VERSION ""

NS_ :

BS_:

BU_: IVT AmsClient Ams PE_FR PE_FL PE_RR FrontNode PE_RL RearNode

BO_ 1 GpsState: 1 RearNode
 SG_ gps_ok : 0|1@1+ (1,0) [0|0] ""  RearNode

BO_ 197 GpsPosition: 8 FrontNode
 SG_ latitude : 0|32@1- (1,0) [0|0] "degrees"  RearNode
 SG_ longitude : 32|32@1- (1,0) [0|0] "degrees"  RearNode

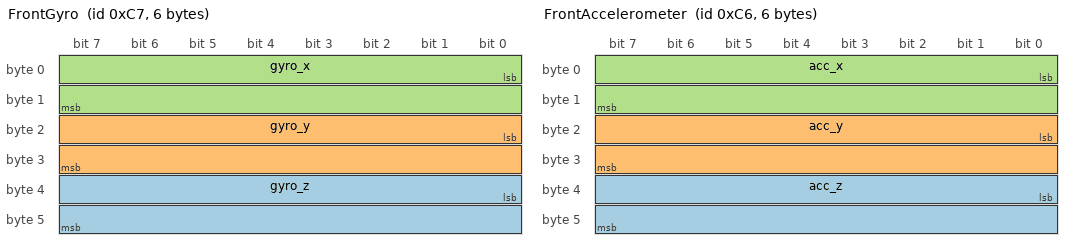
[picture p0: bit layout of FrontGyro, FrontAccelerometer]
BO_ 199 FrontGyro: 6 FrontNode
 SG_ gyro_z : 32|16@1- (1,0) [0|0] ""  FrontNode,RearNode
 SG_ gyro_y : 16|16@1- (1,0) [0|0] ""  FrontNode,RearNode
 SG_ gyro_x : 0|16@1- (1,0) [0|0] ""  FrontNode,RearNode

BO_ 198 FrontAccelerometer: 6 FrontNode
 SG_ acc_z : 32|16@1- (0.001,0) [0|0] "m/s^2"  FrontNode,RearNode
 SG_ acc_y : 16|16@1- (0.001,0) [0|0] "m/s^2"  FrontNode,RearNode
 SG_ acc_x : 0|16@1- (0.001,0) [0|0] "m/s^2"  FrontNode,RearNode

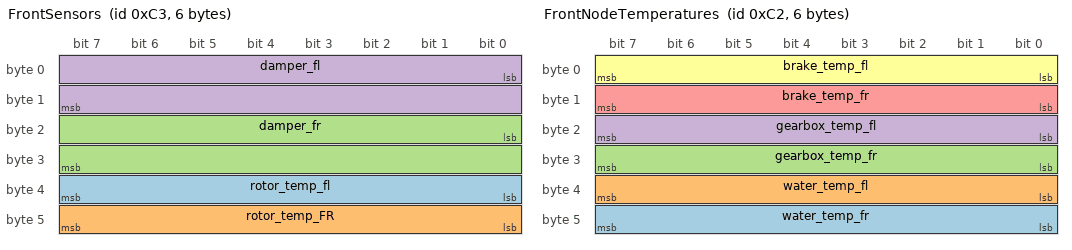
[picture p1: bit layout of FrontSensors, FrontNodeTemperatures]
BO_ 195 FrontSensors: 6 FrontNode
 SG_ rotor_temp_fl : 32|8@1+ (0.5,5) [5|132.5] "" Vector__XXX
 SG_ rotor_temp_FR : 40|8@1+ (0.5,5) [5|132.5] "" Vector__XXX
 SG_ damper_fr : 16|16@1+ (0.01,0) [0|655.35] ""  FrontNode,RearNode
 SG_ damper_fl : 0|16@1+ (0.01,0) [0|655.35] ""  FrontNode,RearNode

BO_ 194 FrontNodeTemperatures: 6 FrontNode
 SG_ water_temp_fr : 40|8@1+ (0.5,5) [5|132.5] "" Vector__XXX
 SG_ water_temp_fl : 32|8@1+ (0.5,5) [5|132.5] "" Vector__XXX
 SG_ gearbox_temp_fr : 24|8@1+ (0.5,5) [5|132.5] ""  FrontNode,RearNode
 SG_ gearbox_temp_fl : 16|8@1+ (0.5,5) [5|132.5] ""  FrontNode,RearNode
 SG_ brake_temp_fr : 8|8@1+ (4,0) [0|0] ""  FrontNode,RearNode
 SG_ brake_temp_fl : 0|8@1+ (4,0) [0|1020] ""  FrontNode,RearNode

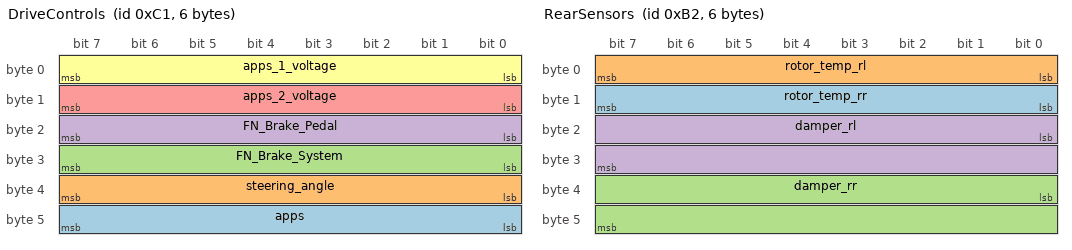
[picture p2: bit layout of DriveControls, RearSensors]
BO_ 193 DriveControls: 6 FrontNode
 SG_ apps : 40|8@1+ (0.5,0) [0|0] ""  FrontNode,RearNode
 SG_ steering_angle : 32|8@1- (2,0) [-256|254] ""  FrontNode,RearNode
 SG_ FN_Brake_System : 24|8@1+ (0.5,0) [0|0] ""  FrontNode,RearNode
 SG_ FN_Brake_Pedal : 16|8@1+ (0.5,0) [0|0] ""  FrontNode,RearNode
 SG_ apps_2_voltage : 8|8@1+ (0.5,0) [0|127.5] ""  FrontNode,RearNode
 SG_ apps_1_voltage : 0|8@1+ (0.5,0) [0|127.5] ""  FrontNode,RearNode

BO_ 178 RearSensors: 6 RearNode
 SG_ rotor_temp_rr : 8|8@1+ (0.5,5) [5|132.5] ""  FrontNode
 SG_ rotor_temp_rl : 0|8@1+ (0.5,5) [5|132.5] ""  FrontNode
 SG_ damper_rr : 32|16@1+ (0.01,0) [0|655.35] ""  FrontNode
 SG_ damper_rl : 16|16@1+ (0.01,0) [0|655.35] ""  FrontNode

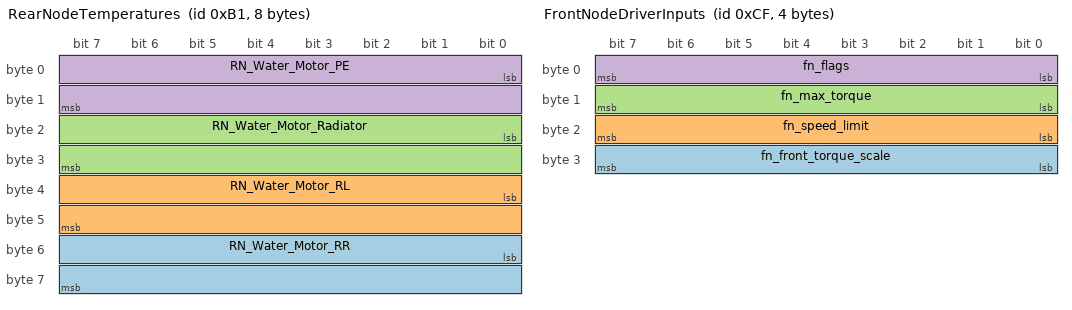
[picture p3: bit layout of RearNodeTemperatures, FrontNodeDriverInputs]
BO_ 177 RearNodeTemperatures: 8 RearNode
 SG_ RN_Water_Motor_RR : 48|16@1+ (0.01,0) [0|655.35] ""  FrontNode
 SG_ RN_Water_Motor_RL : 32|16@1+ (0.01,0) [0|655.35] ""  FrontNode
 SG_ RN_Water_Motor_Radiator : 16|16@1+ (0.01,0) [0|655.35] ""  FrontNode
 SG_ RN_Water_Motor_PE : 0|16@1+ (0.01,0) [0|655.35] ""  FrontNode

BO_ 207 FrontNodeDriverInputs: 4 FrontNode
 SG_ fn_front_torque_scale : 24|8@1+ (0.4,0) [0|102] ""  FrontNode
 SG_ fn_speed_limit : 16|8@1+ (100,0) [0|25500] ""  FrontNode
 SG_ fn_max_torque : 8|8@1+ (0.4,0) [0|102] ""  FrontNode
 SG_ fn_flags : 0|8@1+ (1,0) [0|0] ""  FrontNode,Ams,RearNode

BO_ 191 RearNodeStatus: 4 RearNode
 SG_ rn_state : 0|8@1+ (1,0) [0|0] ""  FrontNode

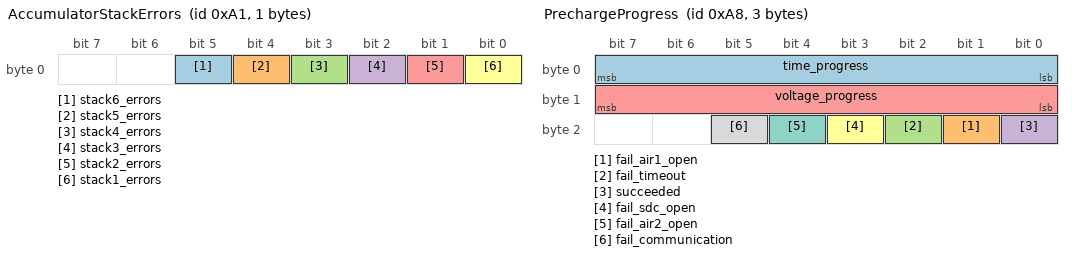
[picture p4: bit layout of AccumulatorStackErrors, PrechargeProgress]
BO_ 161 AccumulatorStackErrors: 1 Ams
 SG_ stack6_errors : 5|1@1+ (1,0) [0|0] ""  FrontNode,AmsClient
 SG_ stack5_errors : 4|1@1+ (1,0) [0|0] ""  FrontNode,AmsClient
 SG_ stack4_errors : 3|1@1+ (1,0) [0|0] ""  FrontNode,AmsClient
 SG_ stack3_errors : 2|1@1+ (1,0) [0|0] ""  FrontNode,AmsClient
 SG_ stack2_errors : 1|1@1+ (1,0) [0|0] ""  FrontNode,AmsClient
 SG_ stack1_errors : 0|1@1+ (1,0) [0|0] ""  FrontNode,AmsClient

BO_ 1320 IVT_Msg_Result_Wh: 6 IVT
 SG_ IVT_ResultState_And_MsgCount_Wh : 8|8@1- (1,0) [0|0] ""  Ams,AmsClient
 SG_ IVT_Result_Wh : 16|32@1- (1,0) [0|0] ""  Ams,AmsClient
 SG_ IVT_MuxID_Wh : 0|8@1+ (1,0) [0|0] ""  Ams,AmsClient

BO_ 1318 IVT_Msg_Result_W: 6 IVT
 SG_ IVT_ResultState_And_MsgCount_W : 8|8@1- (1,0) [0|0] ""  Ams,AmsClient
 SG_ IVT_Result_W : 16|32@1- (1,0) [0|0] ""  Ams,AmsClient
 SG_ IVT_MuxID_W : 0|8@1+ (1,0) [0|0] ""  Ams,AmsClient

BO_ 241 AmsClientStatus: 1 AmsClient
 SG_ AmsClient_Trigger_Ams : 0|1@1+ (1,0) [0|0] ""  Ams
 SG_ AmsClient_Start_TS : 1|1@1+ (1,0) [0|255] ""  Ams

BO_ 168 PrechargeProgress: 3 Ams
 SG_ time_progress : 0|8@1+ (1,0) [0|100] "%"  FrontNode,AmsClient
 SG_ fail_air1_open : 17|1@1+ (1,0) [0|0] "flag"  FrontNode,AmsClient
 SG_ fail_timeout : 18|1@1+ (1,0) [0|0] "flag"  FrontNode,AmsClient
 SG_ succeeded : 16|1@1+ (1,0) [0|0] "flag"  FrontNode,AmsClient
 SG_ voltage_progress : 8|8@1+ (1,0) [0|100] "%"  AmsClient
 SG_ fail_sdc_open : 19|1@1+ (1,0) [0|0] "flag"  AmsClient
 SG_ fail_air2_open : 20|1@1+ (1,0) [0|0] ""  AmsClient
 SG_ fail_communication : 21|1@1+ (1,0) [0|0] ""  AmsClient

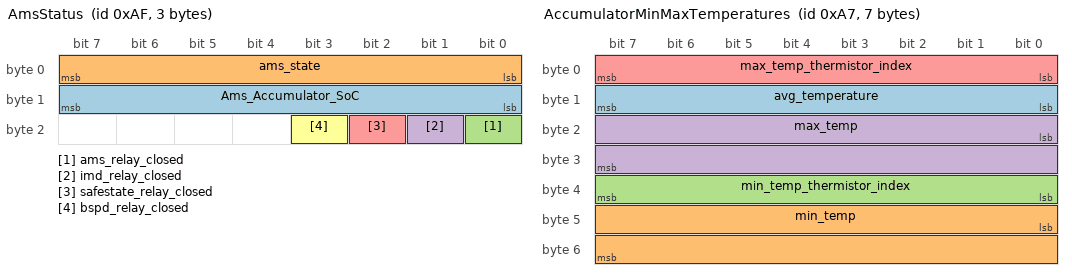
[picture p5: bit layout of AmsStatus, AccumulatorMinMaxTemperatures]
BO_ 175 AmsStatus: 3 Ams
 SG_ Ams_Accumulator_SoC : 8|8@1+ (1,0) [0|255] ""  FrontNode,AmsClient
 SG_ ams_state : 0|8@1+ (1,0) [0|3] ""  FrontNode,AmsClient
 SG_ ams_relay_closed : 16|1@1+ (1,0) [0|0] ""  AmsClient
 SG_ imd_relay_closed : 17|1@1+ (1,0) [0|0] ""  AmsClient
 SG_ safestate_relay_closed : 18|1@1+ (1,0) [0|0] ""  AmsClient
 SG_ bspd_relay_closed : 19|1@1+ (1,0) [0|0] ""  AmsClient

BO_ 167 AccumulatorMinMaxTemperatures: 7 Ams
 SG_ avg_temperature : 8|8@1- (1,0) [0|0] ""  AmsClient
 SG_ min_temp : 40|16@1- (0.01,0) [0|655.35] ""  FrontNode,AmsClient
 SG_ min_temp_thermistor_index : 32|8@1+ (1,0) [0|255] ""  FrontNode,AmsClient
 SG_ max_temp : 16|16@1- (0.01,0) [0|655.35] ""  FrontNode,AmsClient
 SG_ max_temp_thermistor_index : 0|8@1+ (1,0) [0|255] ""  FrontNode,AmsClient

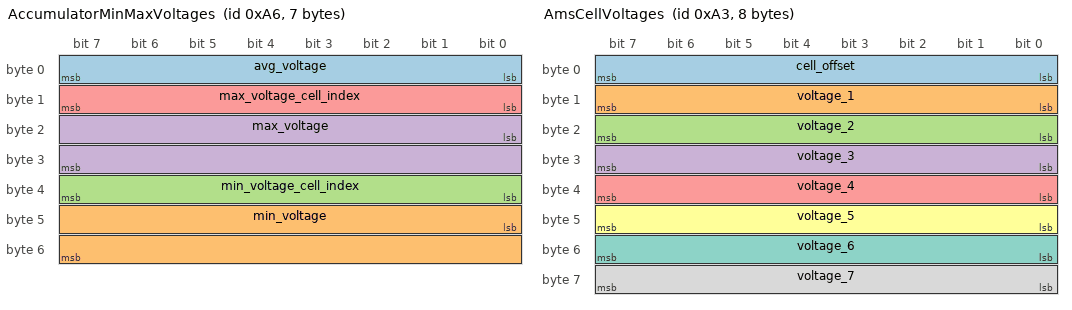
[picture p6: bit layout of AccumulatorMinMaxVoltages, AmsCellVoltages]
BO_ 166 AccumulatorMinMaxVoltages: 7 Ams
 SG_ avg_voltage : 0|8@1- (0.00509804,2.9) [2.9|4.2] ""  AmsClient
 SG_ min_voltage : 40|16@1- (0.001,0) [0|65.535] ""  FrontNode,AmsClient
 SG_ min_voltage_cell_index : 32|8@1+ (1,0) [0|137] ""  FrontNode,AmsClient
 SG_ max_voltage : 16|16@1- (0.001,0) [0|65.535] ""  FrontNode,AmsClient
 SG_ max_voltage_cell_index : 8|8@1+ (1,0) [0|137] ""  FrontNode,AmsClient

BO_ 163 AmsCellVoltages: 8 Ams
 SG_ cell_offset M : 0|8@1+ (1,0) [0|0] ""  AmsClient
 SG_ voltage_1 : 8|8@1- (0.00509804,2.9) [2.9|4.2] "Volt"  AmsClient
 SG_ voltage_2 : 16|8@1- (0.0050980392157,2.9) [2.9|4.2] "Volt"  AmsClient
 SG_ voltage_3 : 24|8@1- (0.0050980392157,2.9) [2.9|4.2] "Volt"  AmsClient
 SG_ voltage_4 : 32|8@1- (0.0050980392157,2.9) [2.9|4.2] "Volt"  AmsClient
 SG_ voltage_5 : 40|8@1- (0.0050980392157,2.9) [2.9|4.2] "Volt"  AmsClient
 SG_ voltage_6 : 48|8@1- (0.0050980392157,2.9) [2.9|4.2] "Volt"  AmsClient
 SG_ voltage_7 : 56|8@1- (0.0050980392157,2.9) [2.9|4.2] "Volt"  AmsClient

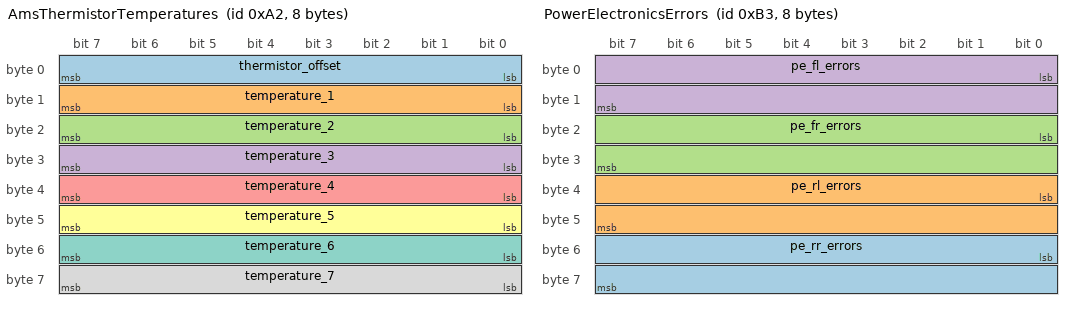
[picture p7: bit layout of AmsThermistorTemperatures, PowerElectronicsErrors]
BO_ 162 AmsThermistorTemperatures: 8 Ams
 SG_ thermistor_offset : 0|8@1+ (1,0) [0|0] ""  AmsClient
 SG_ temperature_1 : 8|8@1+ (0.5,-20) [-20|107.5] "Celsius"  AmsClient
 SG_ temperature_2 : 16|8@1+ (0.5,-20) [-20|107.5] "Celsius"  AmsClient
 SG_ temperature_3 : 24|8@1+ (0.5,-20) [-20|107.5] "Celsius"  AmsClient
 SG_ temperature_4 : 32|8@1+ (0.5,-20) [-20|107.5] "Celsius"  AmsClient
 SG_ temperature_5 : 40|8@1+ (0.5,-20) [-20|107.5] "Celsius"  AmsClient
 SG_ temperature_6 : 48|8@1+ (0.5,-20) [-20|107.5] "Celsius"  AmsClient
 SG_ temperature_7 : 56|8@1+ (0.5,-20) [-20|107.5] "Celsius"  AmsClient

BO_ 1316 IVT_Msg_Result_U3: 6 IVT
 SG_ IVT_ResultState_And_MsgCount_U3 : 8|8@1- (1,0) [0|0] ""  Ams,AmsClient
 SG_ IVT_Result_U3 : 16|32@1- (0.001,0) [-32000|32000] ""  Ams,AmsClient
 SG_ IVT_MuxID_U3 : 0|8@1+ (1,0) [0|0] ""  Ams,AmsClient

BO_ 1315 IVT_Msg_Result_U2: 6 IVT
 SG_ IVT_ResultState_And_MsgCount_U2 : 8|8@1- (1,0) [0|0] ""  Ams,AmsClient
 SG_ IVT_Result_U2 : 16|32@1- (0.001,0) [-32000|32000] ""  Ams,AmsClient
 SG_ IVT_MuxID_U2 : 0|8@1+ (1,0) [0|0] ""  Ams,AmsClient

BO_ 1314 IVT_Msg_Result_U1: 6 IVT
 SG_ IVT_ResultState_And_MsgCount_U1 : 8|8@1- (1,0) [0|0] ""  Ams,AmsClient
 SG_ IVT_Result_U1 : 16|32@1- (0.001,0) [-32000|32000] ""  Ams,AmsClient
 SG_ IVT_MuxID_U1 : 0|8@1+ (1,0) [0|0] ""  Ams,AmsClient

BO_ 1317 IVT_Msg_Result_T: 6 IVT
 SG_ IVT_ResultState_And_MsgCount_T : 8|8@1- (1,0) [0|0] ""  Ams,AmsClient
 SG_ IVT_Result_T : 16|32@1- (0.1,0) [-214748364.8|214748364.7] ""  Ams,AmsClient
 SG_ IVT_MuxID_T : 0|8@1+ (1,0) [0|0] ""  Ams,AmsClient

BO_ 1313 IVT_Msg_Result_I: 6 IVT
 SG_ IVT_ResultState_And_MsgCount_I : 8|8@1- (1,0) [0|0] ""  Ams,AmsClient
 SG_ IVT_Result_I : 16|32@1- (0.001,0) [-32000|32000] ""  Ams,AmsClient
 SG_ IVT_MuxID_I : 0|8@1+ (1,0) [0|0] ""  Ams,AmsClient

BO_ 1319 IVT_Msg_Result_As: 6 IVT
 SG_ IVT_ResultState_And_MsgCount_As : 8|8@1- (1,0) [0|0] ""  Ams,AmsClient
 SG_ IVT_Result_As : 16|32@1- (0.001,0) [-2147483.648|2147483.647] ""  Ams,AmsClient
 SG_ IVT_MuxID_As : 0|8@1+ (1,0) [0|0] ""  Ams,AmsClient

BO_ 179 PowerElectronicsErrors: 8 RearNode
 SG_ pe_rr_errors : 48|16@1- (1,0) [0|0] ""  FrontNode
 SG_ pe_rl_errors : 32|16@1- (1,0) [0|0] ""  FrontNode
 SG_ pe_fr_errors : 16|16@1- (1,0) [0|0] ""  FrontNode
 SG_ pe_fl_errors : 0|16@1- (1,0) [0|0] ""  FrontNode

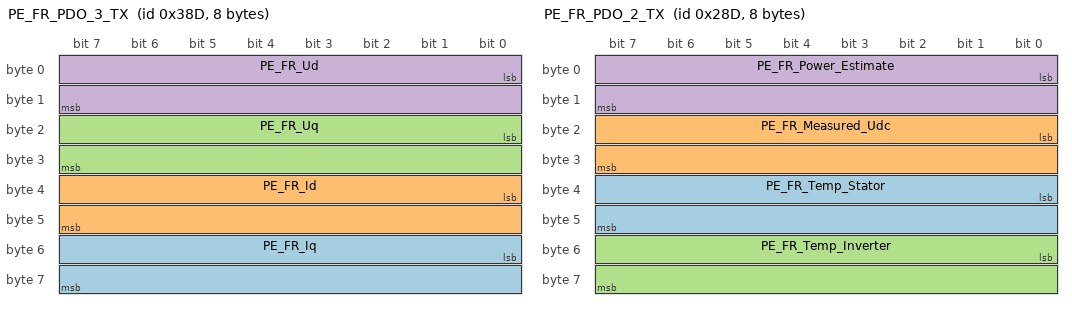
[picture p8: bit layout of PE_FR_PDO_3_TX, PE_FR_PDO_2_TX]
BO_ 909 PE_FR_PDO_3_TX: 8 PE_FR
 SG_ PE_FR_Iq : 48|16@1- (0.1,0) [-3276.8|3276.7] "dA"  RearNode
 SG_ PE_FR_Id : 32|16@1- (0.1,0) [-3276.8|3276.7] "dA"  RearNode
 SG_ PE_FR_Uq : 16|16@1- (0.1,0) [0|0] "dV"  RearNode
 SG_ PE_FR_Ud : 0|16@1- (0.1,0) [0|0] "dV"  RearNode

BO_ 653 PE_FR_PDO_2_TX: 8 PE_FR
 SG_ PE_FR_Temp_Stator : 32|16@1- (1,0) [0|0] "degC"  RearNode
 SG_ PE_FR_Measured_Udc : 16|16@1- (0.1,0) [0|0] "dV"  RearNode
 SG_ PE_FR_Temp_Inverter : 48|16@1- (1,0) [0|0] "degC"  RearNode
 SG_ PE_FR_Power_Estimate : 0|16@1- (10,0) [-327680|327670] "DW"  RearNode

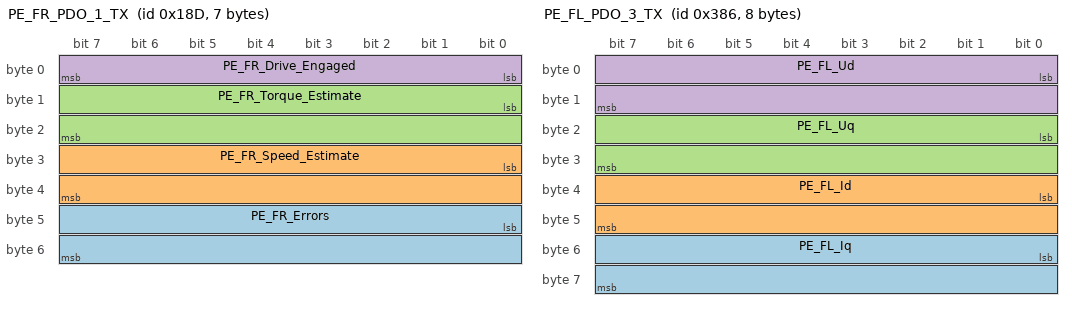
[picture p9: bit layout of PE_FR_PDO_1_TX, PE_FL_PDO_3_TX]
BO_ 397 PE_FR_PDO_1_TX: 7 PE_FR
 SG_ PE_FR_Errors : 40|16@1+ (1,0) [0|0] ""  RearNode
 SG_ PE_FR_Speed_Estimate : 24|16@1- (1,0) [0|0] "RPM"  RearNode
 SG_ PE_FR_Torque_Estimate : 8|16@1- (0.001,0) [-32.768|32.767] "mNm"  RearNode
 SG_ PE_FR_Drive_Engaged : 0|8@1+ (1,0) [0|0] ""  RearNode

BO_ 902 PE_FL_PDO_3_TX: 8 PE_FL
 SG_ PE_FL_Iq : 48|16@1- (0.1,0) [-3276.8|3276.7] "dA"  RearNode
 SG_ PE_FL_Id : 32|16@1- (0.1,0) [-3276.8|3276.7] "dA"  RearNode
 SG_ PE_FL_Uq : 16|16@1- (0.1,0) [0|0] "dV"  RearNode
 SG_ PE_FL_Ud : 0|16@1- (0.1,0) [0|0] "dV"  RearNode

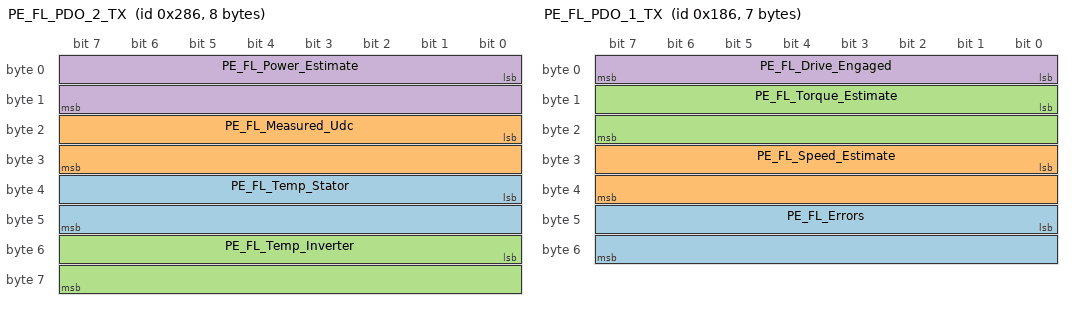
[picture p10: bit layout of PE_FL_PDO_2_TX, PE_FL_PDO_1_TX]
BO_ 646 PE_FL_PDO_2_TX: 8 PE_FL
 SG_ PE_FL_Temp_Stator : 32|16@1- (1,0) [0|0] "degC"  RearNode
 SG_ PE_FL_Measured_Udc : 16|16@1- (0.1,0) [0|0] "dV"  RearNode
 SG_ PE_FL_Temp_Inverter : 48|16@1- (1,0) [0|0] "degC"  RearNode
 SG_ PE_FL_Power_Estimate : 0|16@1- (10,0) [-327680|327670] "DW"  RearNode

BO_ 390 PE_FL_PDO_1_TX: 7 PE_FL
 SG_ PE_FL_Errors : 40|16@1+ (1,0) [0|0] ""  RearNode
 SG_ PE_FL_Speed_Estimate : 24|16@1- (1,0) [0|0] "RPM"  RearNode
 SG_ PE_FL_Torque_Estimate : 8|16@1- (0.001,0) [-32.768|32.767] "mNm"  RearNode
 SG_ PE_FL_Drive_Engaged : 0|8@1+ (1,0) [0|0] ""  RearNode

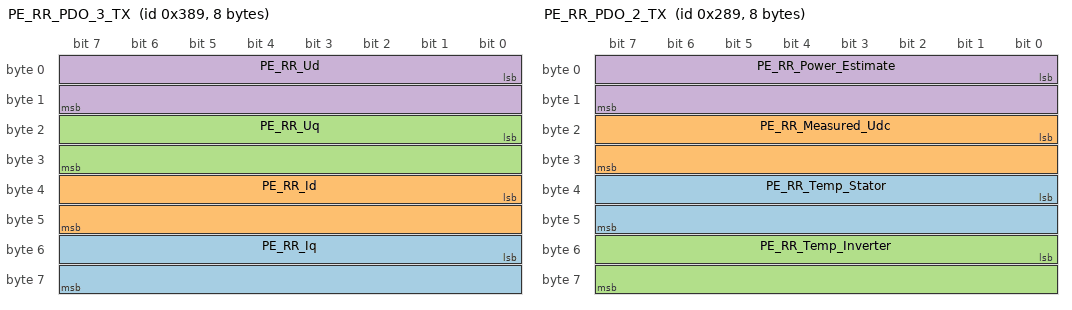
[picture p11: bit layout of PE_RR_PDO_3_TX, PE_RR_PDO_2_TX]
BO_ 905 PE_RR_PDO_3_TX: 8 PE_RR
 SG_ PE_RR_Iq : 48|16@1- (0.1,0) [-3276.8|3276.7] "dA"  RearNode
 SG_ PE_RR_Id : 32|16@1- (0.1,0) [-3276.8|3276.7] "dA"  RearNode
 SG_ PE_RR_Uq : 16|16@1- (0.1,0) [0|0] "dV"  RearNode
 SG_ PE_RR_Ud : 0|16@1- (0.1,0) [0|0] "dV"  RearNode

BO_ 649 PE_RR_PDO_2_TX: 8 PE_RR
 SG_ PE_RR_Temp_Stator : 32|16@1- (1,0) [0|0] "degC"  RearNode
 SG_ PE_RR_Measured_Udc : 16|16@1- (0.1,0) [0|0] "dV"  RearNode
 SG_ PE_RR_Temp_Inverter : 48|16@1- (1,0) [0|0] "degC"  RearNode
 SG_ PE_RR_Power_Estimate : 0|16@1- (10,0) [-327680|327670] "DW"  RearNode

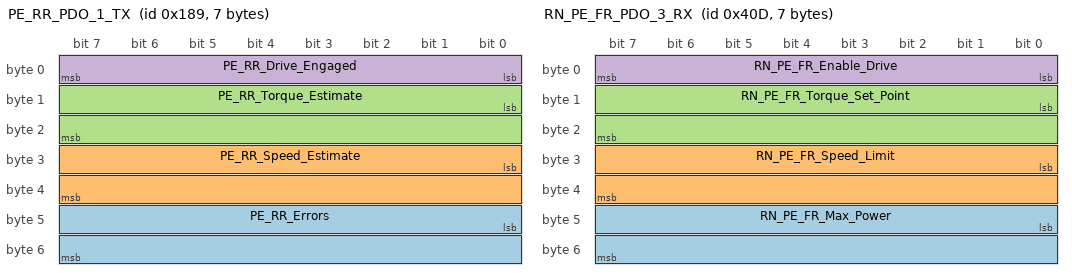
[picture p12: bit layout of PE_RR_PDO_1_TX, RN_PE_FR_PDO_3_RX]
BO_ 393 PE_RR_PDO_1_TX: 7 PE_RR
 SG_ PE_RR_Errors : 40|16@1+ (1,0) [0|0] ""  RearNode
 SG_ PE_RR_Speed_Estimate : 24|16@1- (1,0) [0|0] "RPM"  RearNode
 SG_ PE_RR_Torque_Estimate : 8|16@1- (0.001,0) [-32.768|32.767] "mNm"  RearNode
 SG_ PE_RR_Drive_Engaged : 0|8@1+ (1,0) [0|0] ""  RearNode

BO_ 1037 RN_PE_FR_PDO_3_RX: 7 RearNode
 SG_ RN_PE_FR_Max_Power : 40|16@1+ (10,0) [0|655350] "DW"  PE_FR
 SG_ RN_PE_FR_Speed_Limit : 24|16@1- (1,0) [0|0] "RPM"  PE_FR
 SG_ RN_PE_FR_Torque_Set_Point : 8|16@1- (0.001,0) [-32.768|32.767] "mNm"  PE_FR
 SG_ RN_PE_FR_Enable_Drive : 0|8@1+ (1,0) [0|0] ""  PE_FR

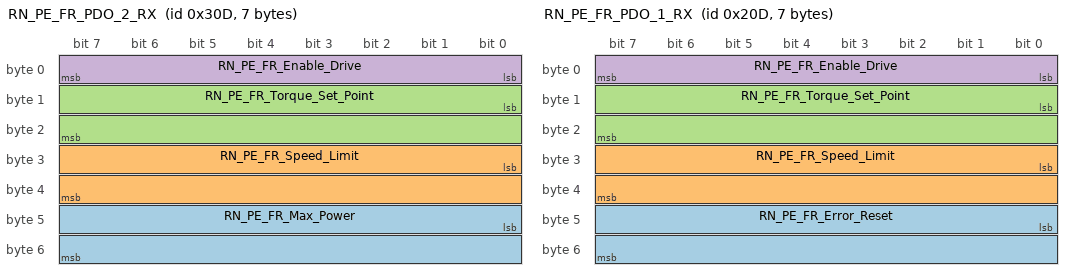
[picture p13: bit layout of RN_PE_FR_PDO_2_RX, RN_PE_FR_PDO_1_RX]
BO_ 781 RN_PE_FR_PDO_2_RX: 7 RearNode
 SG_ RN_PE_FR_Max_Power : 40|16@1+ (10,0) [0|655350] "DW"  PE_FR
 SG_ RN_PE_FR_Speed_Limit : 24|16@1- (1,0) [0|0] "RPM"  PE_FR
 SG_ RN_PE_FR_Torque_Set_Point : 8|16@1- (0.001,0) [-32.768|32.767] "mNm"  PE_FR
 SG_ RN_PE_FR_Enable_Drive : 0|8@1+ (1,0) [0|0] ""  PE_FR

BO_ 525 RN_PE_FR_PDO_1_RX: 7 RearNode
 SG_ RN_PE_FR_Error_Reset : 40|16@1+ (1,0) [0|0] ""  PE_FR
 SG_ RN_PE_FR_Speed_Limit : 24|16@1- (1,0) [0|0] "RPM"  PE_FR
 SG_ RN_PE_FR_Torque_Set_Point : 8|16@1- (0.001,0) [-32.768|32.767] "mNm"  PE_FR
 SG_ RN_PE_FR_Enable_Drive : 0|8@1+ (1,0) [0|0] ""  PE_FR

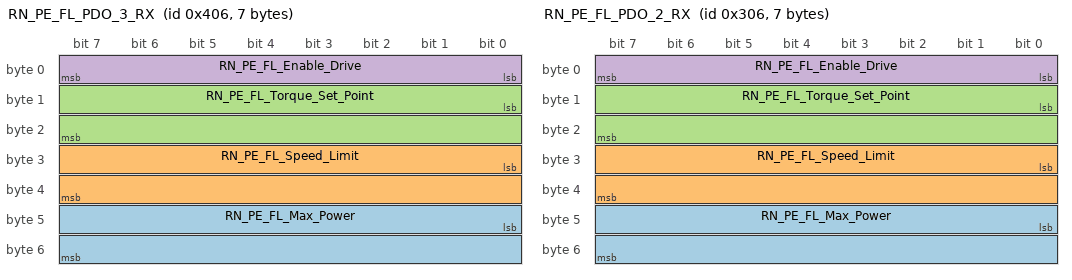
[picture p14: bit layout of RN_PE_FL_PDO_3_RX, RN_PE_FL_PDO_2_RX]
BO_ 1030 RN_PE_FL_PDO_3_RX: 7 RearNode
 SG_ RN_PE_FL_Max_Power : 40|16@1+ (10,0) [0|655350] "DW"  PE_FL
 SG_ RN_PE_FL_Speed_Limit : 24|16@1- (1,0) [0|0] "RPM"  PE_FL
 SG_ RN_PE_FL_Torque_Set_Point : 8|16@1- (0.001,0) [-32.768|32.767] "mNm"  PE_FL
 SG_ RN_PE_FL_Enable_Drive : 0|8@1+ (1,0) [0|0] ""  PE_FL

BO_ 774 RN_PE_FL_PDO_2_RX: 7 RearNode
 SG_ RN_PE_FL_Max_Power : 40|16@1+ (10,0) [0|655350] "DW"  PE_FL
 SG_ RN_PE_FL_Speed_Limit : 24|16@1- (1,0) [0|0] "RPM"  PE_FL
 SG_ RN_PE_FL_Torque_Set_Point : 8|16@1- (0.001,0) [-32.768|32.767] "mNm"  PE_FL
 SG_ RN_PE_FL_Enable_Drive : 0|8@1+ (1,0) [0|0] ""  PE_FL

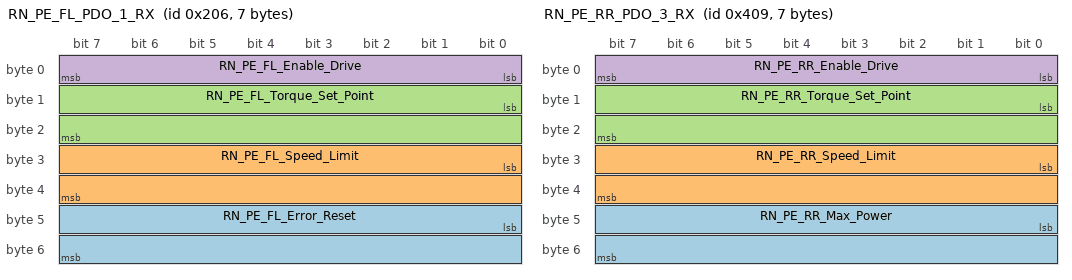
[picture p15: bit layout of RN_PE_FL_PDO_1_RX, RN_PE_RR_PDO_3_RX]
BO_ 518 RN_PE_FL_PDO_1_RX: 7 RearNode
 SG_ RN_PE_FL_Error_Reset : 40|16@1+ (1,0) [0|0] ""  PE_FL
 SG_ RN_PE_FL_Speed_Limit : 24|16@1- (1,0) [0|0] "RPM"  PE_FL
 SG_ RN_PE_FL_Torque_Set_Point : 8|16@1- (0.001,0) [-32.768|32.767] "mNm"  PE_FL
 SG_ RN_PE_FL_Enable_Drive : 0|8@1+ (1,0) [0|0] ""  PE_FL

BO_ 1033 RN_PE_RR_PDO_3_RX: 7 RearNode
 SG_ RN_PE_RR_Max_Power : 40|16@1+ (10,0) [0|655350] "DW"  PE_RR
 SG_ RN_PE_RR_Speed_Limit : 24|16@1- (1,0) [0|0] "RPM"  PE_RR
 SG_ RN_PE_RR_Torque_Set_Point : 8|16@1- (0.001,0) [-32.768|32.767] "mNm"  PE_RR
 SG_ RN_PE_RR_Enable_Drive : 0|8@1+ (1,0) [0|0] ""  PE_RR

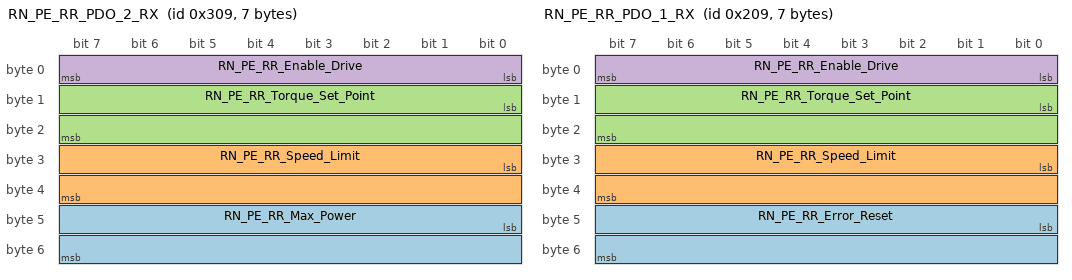
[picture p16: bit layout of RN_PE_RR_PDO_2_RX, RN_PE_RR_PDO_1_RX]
BO_ 777 RN_PE_RR_PDO_2_RX: 7 RearNode
 SG_ RN_PE_RR_Max_Power : 40|16@1+ (10,0) [0|655350] "DW"  PE_RR
 SG_ RN_PE_RR_Speed_Limit : 24|16@1- (1,0) [0|0] "RPM"  PE_RR
 SG_ RN_PE_RR_Torque_Set_Point : 8|16@1- (0.001,0) [-32.768|32.767] "mNm"  PE_RR
 SG_ RN_PE_RR_Enable_Drive : 0|8@1+ (1,0) [0|0] ""  PE_RR

BO_ 521 RN_PE_RR_PDO_1_RX: 7 RearNode
 SG_ RN_PE_RR_Error_Reset : 40|16@1+ (1,0) [0|0] ""  PE_RR
 SG_ RN_PE_RR_Speed_Limit : 24|16@1- (1,0) [0|0] "RPM"  PE_RR
 SG_ RN_PE_RR_Torque_Set_Point : 8|16@1- (0.001,0) [-32.768|32.767] "mNm"  PE_RR
 SG_ RN_PE_RR_Enable_Drive : 0|8@1+ (1,0) [0|0] ""  PE_RR

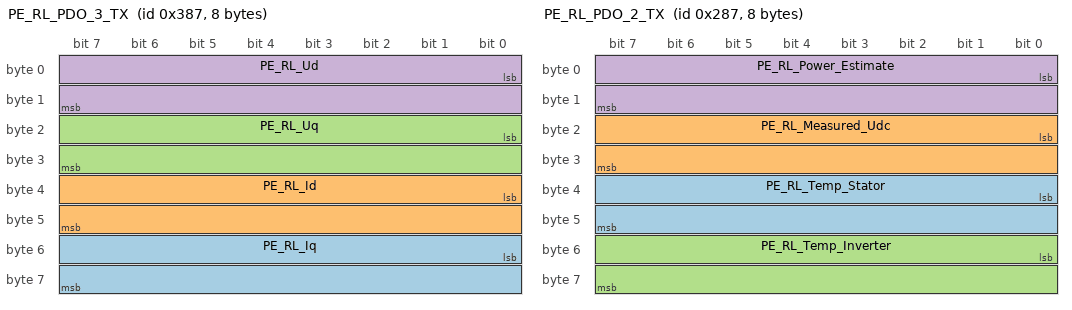
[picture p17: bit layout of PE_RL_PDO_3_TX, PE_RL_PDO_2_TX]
BO_ 903 PE_RL_PDO_3_TX: 8 PE_RL
 SG_ PE_RL_Iq : 48|16@1- (0.1,0) [-3276.8|3276.7] "dA"  RearNode
 SG_ PE_RL_Id : 32|16@1- (0.1,0) [-3276.8|3276.7] "dA"  RearNode
 SG_ PE_RL_Uq : 16|16@1- (0.1,0) [0|0] "dV"  RearNode
 SG_ PE_RL_Ud : 0|16@1- (0.1,0) [0|0] "dV"  RearNode

BO_ 647 PE_RL_PDO_2_TX: 8 PE_RL
 SG_ PE_RL_Temp_Stator : 32|16@1- (1,0) [0|0] "degC"  RearNode
 SG_ PE_RL_Measured_Udc : 16|16@1- (0.1,0) [0|0] "dV"  RearNode
 SG_ PE_RL_Temp_Inverter : 48|16@1- (1,0) [0|0] "degC"  RearNode
 SG_ PE_RL_Power_Estimate : 0|16@1- (10,0) [-327680|327670] "DW"  RearNode

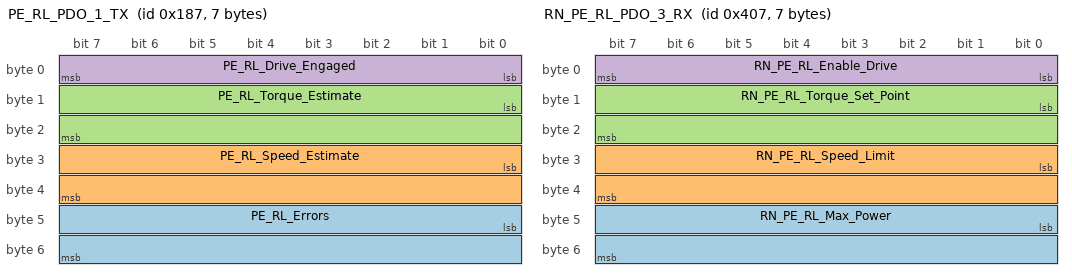
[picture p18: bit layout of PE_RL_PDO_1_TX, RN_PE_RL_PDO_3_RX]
BO_ 391 PE_RL_PDO_1_TX: 7 PE_RL
 SG_ PE_RL_Errors : 40|16@1+ (1,0) [0|0] ""  RearNode
 SG_ PE_RL_Speed_Estimate : 24|16@1- (1,0) [0|0] "RPM"  RearNode
 SG_ PE_RL_Torque_Estimate : 8|16@1- (0.001,0) [-32.768|32.767] "mNm"  RearNode
 SG_ PE_RL_Drive_Engaged : 0|8@1+ (1,0) [0|0] ""  RearNode

BO_ 1031 RN_PE_RL_PDO_3_RX: 7 RearNode
 SG_ RN_PE_RL_Max_Power : 40|16@1+ (10,0) [0|655350] "DW"  PE_RL
 SG_ RN_PE_RL_Speed_Limit : 24|16@1- (1,0) [0|0] "RPM"  PE_RL
 SG_ RN_PE_RL_Torque_Set_Point : 8|16@1- (0.001,0) [-32.768|32.767] "mNm"  PE_RL
 SG_ RN_PE_RL_Enable_Drive : 0|8@1+ (1,0) [0|0] ""  PE_RL

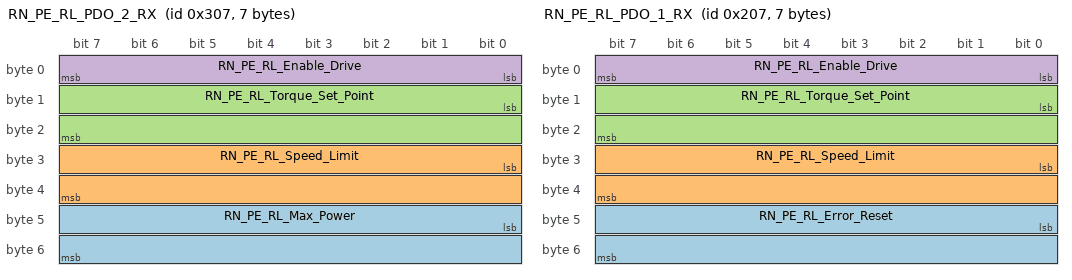
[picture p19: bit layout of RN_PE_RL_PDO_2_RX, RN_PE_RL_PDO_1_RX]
BO_ 775 RN_PE_RL_PDO_2_RX: 7 RearNode
 SG_ RN_PE_RL_Max_Power : 40|16@1+ (10,0) [0|655350] "DW"  PE_RL
 SG_ RN_PE_RL_Speed_Limit : 24|16@1- (1,0) [0|0] "RPM"  PE_RL
 SG_ RN_PE_RL_Torque_Set_Point : 8|16@1- (0.001,0) [-32.768|32.767] "mNm"  PE_RL
 SG_ RN_PE_RL_Enable_Drive : 0|8@1+ (1,0) [0|0] ""  PE_RL

BO_ 519 RN_PE_RL_PDO_1_RX: 7 RearNode
 SG_ RN_PE_RL_Error_Reset : 40|16@1+ (1,0) [0|0] ""  PE_RL
 SG_ RN_PE_RL_Speed_Limit : 24|16@1- (1,0) [0|0] "RPM"  PE_RL
 SG_ RN_PE_RL_Torque_Set_Point : 8|16@1- (0.001,0) [-32.768|32.767] "mNm"  PE_RL
 SG_ RN_PE_RL_Enable_Drive : 0|8@1+ (1,0) [0|0] ""  PE_RL

BO_ 1801 PE_RR_NMT: 1 PE_RR
 SG_ pe_rr_nmt : 0|8@1+ (1,0) [0|255] ""  RearNode

BO_ 1799 PE_RL_NMT: 1 PE_RL
 SG_ pe_rl_nmt : 0|8@1+ (1,0) [0|255] ""  RearNode

BO_ 1805 PE_FR_NMT: 1 PE_FR
 SG_ pe_fr_nmt : 0|8@1+ (1,0) [0|255] ""  RearNode

BO_ 1798 PE_FL_NMT: 1 PE_FL
 SG_ pe_fl_nmt : 0|8@1+ (1,0) [0|255] ""  RearNode

BO_ 2 FrontNodeRequests: 1 FrontNode
 SG_ fn_request : 0|8@1+ (1,0) [0|0] "" Vector__XXX

BO_ 3 FrontNodeStatus: 1 FrontNode
 SG_ fn_state : 0|8@1+ (1,0) [0|0] "" Vector__XXX

BO_ 300 PrechargeRequest: 0 FrontNode

CM_ SG_ 207 fn_flags "TS_Start,R2D,Fan, Pumps, DRS_Driver_Activate, APPS_Implausibility, Brake_APPS_Implausibility";
CM_ SG_ 191 rn_state "Idle=0,Ready=1,Drive=2
";
CM_ SG_ 175 ams_state "Idle=0, Ready=1, Precharging=2, Drive=3
";
CM_ SG_ 1037 RN_PE_FR_Torque_Set_Point "22.5 Nm = 24 Nm, due to error in torque calculation, will be fixed later on";
CM_ SG_ 781 RN_PE_FR_Torque_Set_Point "22.5 Nm = 24 Nm, due to error in torque calculation, will be fixed later on";
CM_ SG_ 525 RN_PE_FR_Torque_Set_Point "22.5 Nm = 24 Nm, due to error in torque calculation, will be fixed later on";
CM_ SG_ 1030 RN_PE_FL_Torque_Set_Point "22.5 Nm = 24 Nm, due to error in torque calculation, will be fixed later on";
CM_ SG_ 774 RN_PE_FL_Torque_Set_Point "22.5 Nm = 24 Nm, due to error in torque calculation, will be fixed later on";
CM_ SG_ 518 RN_PE_FL_Torque_Set_Point "22.5 Nm = 24 Nm, due to error in torque calculation, will be fixed later on";
CM_ SG_ 1033 RN_PE_RR_Torque_Set_Point "22.5 Nm = 24 Nm, due to error in torque calculation, will be fixed later on";
CM_ SG_ 777 RN_PE_RR_Torque_Set_Point "22.5 Nm = 24 Nm, due to error in torque calculation, will be fixed later on";
CM_ SG_ 521 RN_PE_RR_Torque_Set_Point "22.5 Nm = 24 Nm, due to error in torque calculation, will be fixed later on";
CM_ SG_ 1031 RN_PE_RL_Torque_Set_Point "22.5 Nm = 24 Nm, due to error in torque calculation, will be fixed later on";
CM_ SG_ 775 RN_PE_RL_Torque_Set_Point "22.5 Nm = 24 Nm, due to error in torque calculation, will be fixed later on";
CM_ SG_ 519 RN_PE_RL_Torque_Set_Point "22.5 Nm = 24 Nm, due to error in torque calculation, will be fixed later on";
CM_ SG_ 2 fn_request "bit1-r2d,bit2-ts0n-bit3-precharge,bit4-AppsImplausibility,bit5-Apps-BrakeImplausibility,bit6-Pumps,bit7-Fans";
CM_ SG_ 3 fn_state "Idle=0,Ready=1,Drive=2
";
BA_DEF_ BO_  "Bus" ENUM  "CAN1","CAN2","CAN3";
BA_DEF_ SG_  "InternalType" ENUM  "int","float";
BA_DEF_ SG_  "GenSigEnvVarType" ENUM  "int","float","undef";
BA_DEF_ SG_  "GenSigSendType" ENUM  "Cyclic","OnWrite","OnWriteWithRepetition","OnChange","OnChangeWithRepetition","IfActive","IfActiveWithRepetition";
BA_DEF_ BO_  "GenMsgCycleTime" INT 2 2000;
BA_DEF_ BO_  "GenMsgSendType" ENUM  "Cyclic","not_used","not_used","not_used","not_used","Cyclic","not_used","IfActive";
BA_DEF_ BO_  "GenMsgDelayTime" INT 1 1000;
BA_DEF_ BO_  "GenMsgCycleTimeFast" INT 2 50000;
BA_DEF_ BO_  "GenMsgILSupport" ENUM  "No","Yes";
BA_DEF_ BU_  "TpTxIdentifier" HEX 1536 1791;
BA_DEF_ BU_  "TpRxIdentifier" HEX 1536 1791;
BA_DEF_ BU_  "TpRxMask" HEX 0 255;
BA_DEF_ BU_  "TpCanBus" INT 0 2;
BA_DEF_ BU_  "TpUseFC" INT 0 1;
BA_DEF_ BU_  "TpNodeBaseAddress" HEX 0 33554431;
BA_DEF_  "GenEnvVarEndingDsp" STRING ;
BA_DEF_  "GenEnvVarEndingSnd" STRING ;
BA_DEF_  "GenEnvVarPrefix" STRING ;
BA_DEF_  "GenNWMTalkNM" STRING ;
BA_DEF_  "GenNWMGotoMode_BusSleep" STRING ;
BA_DEF_  "GenNWMGotoMode_Awake" STRING ;
BA_DEF_  "GenNWMApCanSleep" STRING ;
BA_DEF_  "GenNWMApCanOn" STRING ;
BA_DEF_  "GenNWMApCanOff" STRING ;
BA_DEF_  "NmBaseAddress" HEX 1280 1311;
BA_DEF_  "BusType" STRING ;
BA_DEF_DEF_  "Bus" "CAN1";
BA_DEF_DEF_  "InternalType" "int";
BA_DEF_DEF_  "GenSigEnvVarType" "undef";
BA_DEF_DEF_  "GenSigSendType" "Cyclic";
BA_DEF_DEF_  "GenMsgCycleTime" 10;
BA_DEF_DEF_  "GenMsgSendType" "Cyclic";
BA_DEF_DEF_  "GenMsgDelayTime" 1;
BA_DEF_DEF_  "GenMsgCycleTimeFast" 5;
BA_DEF_DEF_  "GenMsgILSupport" "Yes";
BA_DEF_DEF_  "TpTxIdentifier" 1536;
BA_DEF_DEF_  "TpRxIdentifier" 1536;
BA_DEF_DEF_  "TpRxMask" 255;
BA_DEF_DEF_  "TpCanBus" 1;
BA_DEF_DEF_  "TpUseFC" 1;
BA_DEF_DEF_  "TpNodeBaseAddress" 1536;
BA_DEF_DEF_  "GenEnvVarEndingDsp" "Dsp_";
BA_DEF_DEF_  "GenEnvVarEndingSnd" "_";
BA_DEF_DEF_  "GenEnvVarPrefix" "Env";
BA_DEF_DEF_  "GenNWMTalkNM" "TalkNM()";
BA_DEF_DEF_  "GenNWMGotoMode_BusSleep" "GotoMode_BusSleep()";
BA_DEF_DEF_  "GenNWMGotoMode_Awake" "GotoMode_Awake()";
BA_DEF_DEF_  "GenNWMApCanSleep" "apCanSleep()";
BA_DEF_DEF_  "GenNWMApCanOn" "apCanOn()";
BA_DEF_DEF_  "GenNWMApCanOff" "apCanOff()";
BA_DEF_DEF_  "NmBaseAddress" 1280;
BA_DEF_DEF_  "BusType" "";
BA_ "BusType" "CAN";
BA_ "InternalType" SG_ 194 water_temp_fl 1;
BA_ "InternalType" SG_ 194 gearbox_temp_fr 1;
BA_ "InternalType" SG_ 194 gearbox_temp_fl 1;
BA_ "InternalType" SG_ 194 brake_temp_fr 1;
BA_ "InternalType" SG_ 194 brake_temp_fl 1;
BA_ "InternalType" SG_ 193 apps 1;
BA_ "InternalType" SG_ 193 steering_angle 1;
BA_ "InternalType" SG_ 193 FN_Brake_System 1;
BA_ "InternalType" SG_ 193 FN_Brake_Pedal 1;
BA_ "InternalType" SG_ 193 apps_2_voltage 1;
BA_ "InternalType" SG_ 193 apps_1_voltage 1;
BA_ "InternalType" SG_ 178 rotor_temp_rr 1;
BA_ "InternalType" SG_ 178 rotor_temp_rl 1;
BA_ "InternalType" SG_ 178 damper_rr 1;
BA_ "InternalType" SG_ 178 damper_rl 1;
BA_ "InternalType" SG_ 177 RN_Water_Motor_RR 1;
BA_ "InternalType" SG_ 177 RN_Water_Motor_RL 1;
BA_ "InternalType" SG_ 177 RN_Water_Motor_Radiator 1;
BA_ "InternalType" SG_ 177 RN_Water_Motor_PE 1;
BA_ "InternalType" SG_ 207 fn_front_torque_scale 1;
BA_ "InternalType" SG_ 207 fn_speed_limit 1;
BA_ "InternalType" SG_ 207 fn_max_torque 1;
BA_ "InternalType" SG_ 167 avg_temperature 1;
BA_ "InternalType" SG_ 167 min_temp 1;
BA_ "InternalType" SG_ 167 max_temp 1;
BA_ "InternalType" SG_ 166 avg_voltage 1;
BA_ "InternalType" SG_ 166 min_voltage 1;
BA_ "InternalType" SG_ 166 max_voltage 1;
BA_ "InternalType" BO_ 163 1;
BA_ "InternalType" BO_ 163 1;
BA_ "InternalType" BO_ 162 1;
BA_ "InternalType" SG_ 1316 IVT_Result_U3 1;
BA_ "InternalType" SG_ 1315 IVT_Result_U2 1;
BA_ "InternalType" SG_ 1314 IVT_Result_U1 1;
BA_ "InternalType" SG_ 1317 IVT_Result_T 1;
BA_ "InternalType" SG_ 1313 IVT_Result_I 1;
BA_ "InternalType" SG_ 1319 IVT_Result_As 1;
BA_ "InternalType" SG_ 909 PE_FR_Iq 1;
BA_ "InternalType" SG_ 909 PE_FR_Id 1;
BA_ "InternalType" SG_ 909 PE_FR_Uq 1;
BA_ "InternalType" SG_ 909 PE_FR_Ud 1;
BA_ "InternalType" SG_ 653 PE_FR_Measured_Udc 1;
BA_ "InternalType" SG_ 397 PE_FR_Torque_Estimate 1;
BA_ "InternalType" SG_ 902 PE_FL_Iq 1;
BA_ "InternalType" SG_ 902 PE_FL_Id 1;
BA_ "InternalType" SG_ 902 PE_FL_Uq 1;
BA_ "InternalType" SG_ 902 PE_FL_Ud 1;
BA_ "InternalType" SG_ 646 PE_FL_Measured_Udc 1;
BA_ "InternalType" SG_ 390 PE_FL_Torque_Estimate 1;
BA_ "InternalType" SG_ 905 PE_RR_Iq 1;
BA_ "InternalType" SG_ 905 PE_RR_Id 1;
BA_ "InternalType" SG_ 905 PE_RR_Uq 1;
BA_ "InternalType" SG_ 905 PE_RR_Ud 1;
BA_ "InternalType" SG_ 649 PE_RR_Measured_Udc 1;
BA_ "InternalType" SG_ 393 PE_RR_Torque_Estimate 1;
BA_ "Bus" BO_ 1037 1;
BA_ "InternalType" SG_ 1037 RN_PE_FR_Torque_Set_Point 1;
BA_ "Bus" BO_ 781 1;
BA_ "InternalType" SG_ 781 RN_PE_FR_Torque_Set_Point 1;
BA_ "Bus" BO_ 525 1;
BA_ "InternalType" SG_ 525 RN_PE_FR_Torque_Set_Point 1;
BA_ "Bus" BO_ 1030 1;
BA_ "InternalType" SG_ 1030 RN_PE_FL_Torque_Set_Point 1;
BA_ "Bus" BO_ 774 1;
BA_ "InternalType" SG_ 774 RN_PE_FL_Torque_Set_Point 1;
BA_ "Bus" BO_ 518 1;
BA_ "InternalType" SG_ 518 RN_PE_FL_Torque_Set_Point 1;
BA_ "Bus" BO_ 1033 1;
BA_ "InternalType" SG_ 1033 RN_PE_RR_Torque_Set_Point 1;
BA_ "Bus" BO_ 777 1;
BA_ "InternalType" SG_ 777 RN_PE_RR_Torque_Set_Point 1;
BA_ "Bus" BO_ 521 1;
BA_ "InternalType" SG_ 521 RN_PE_RR_Torque_Set_Point 1;
BA_ "InternalType" SG_ 903 PE_RL_Iq 1;
BA_ "InternalType" SG_ 903 PE_RL_Id 1;
BA_ "InternalType" SG_ 903 PE_RL_Uq 1;
BA_ "InternalType" SG_ 903 PE_RL_Ud 1;
BA_ "InternalType" SG_ 647 PE_RL_Measured_Udc 1;
BA_ "InternalType" SG_ 391 PE_RL_Torque_Estimate 1;
BA_ "Bus" BO_ 1031 1;
BA_ "InternalType" SG_ 1031 RN_PE_RL_Torque_Set_Point 1;
BA_ "Bus" BO_ 775 1;
BA_ "InternalType" SG_ 775 RN_PE_RL_Torque_Set_Point 1;
BA_ "Bus" BO_ 519 1;
BA_ "InternalType" SG_ 519 RN_PE_RL_Torque_Set_Point 1;
BA_ "Bus" BO_ 1801 1;
BA_ "Bus" BO_ 1799 1;
BA_ "Bus" BO_ 1805 1;
BA_ "Bus" BO_ 1798 1;
SIG_VALTYPE_ 197 latitude : 1;
SIG_VALTYPE_ 197 longitude : 1;
SIG_VALTYPE_ 198 acc_z : 1;
SIG_VALTYPE_ 198 acc_y : 1;
SIG_VALTYPE_ 198 acc_x : 1;
SIG_VALTYPE_ 167 min_temp : 1;
SIG_VALTYPE_ 167 max_temp : 1;
SIG_VALTYPE_ 166 avg_voltage : 1;
SIG_VALTYPE_ 166 min_voltage : 1;
SIG_VALTYPE_ 166 max_voltage : 1;
SIG_VALTYPE_ 163 voltage_1 : 1;
SIG_VALTYPE_ 163 voltage_2 : 1;
SIG_VALTYPE_ 163 voltage_3 : 1;
SIG_VALTYPE_ 163 voltage_4 : 1;
SIG_VALTYPE_ 163 voltage_5 : 1;
SIG_VALTYPE_ 163 voltage_6 : 1;
SIG_VALTYPE_ 163 voltage_7 : 1;
